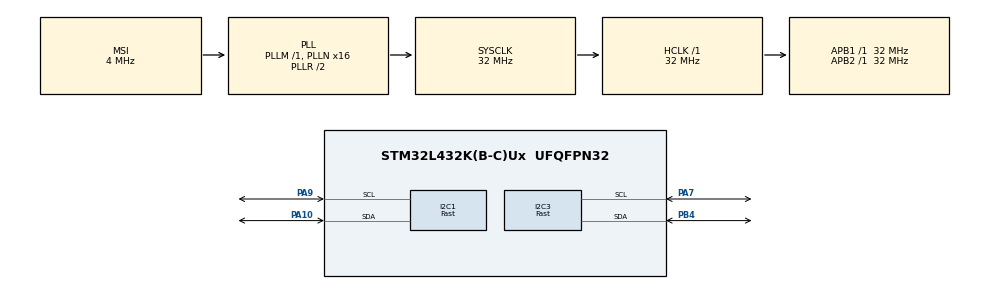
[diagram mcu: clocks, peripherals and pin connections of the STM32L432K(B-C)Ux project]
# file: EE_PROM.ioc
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I2C1.I2C_Speed_Mode=I2C_Fast
I2C1.Timing=0x00300F38
I2C3.I2C_Speed_Mode=I2C_Fast
I2C3.Timing=0x00300F38
Mcu.Family=STM32L4
Mcu.Name=STM32L432K(B-C)Ux
Mcu.Package=UFQFPN32
NVIC.PriorityGroup=NVIC_PRIORITYGROUP_4
PA10.Mode=I2C
PA10.Signal=I2C1_SDA
PA13\ (JTMS-SWDIO).Mode=Serial_Wire
PA13\ (JTMS-SWDIO).Signal=SYS_JTMS-SWDIO
PA14\ (JTCK-SWCLK).Mode=Serial_Wire
PA14\ (JTCK-SWCLK).Signal=SYS_JTCK-SWCLK
PA7.Mode=I2C
PA7.Signal=I2C3_SCL
PA9.Mode=I2C
PA9.Signal=I2C1_SCL
PB4\ (NJTRST).Mode=I2C
PB4\ (NJTRST).Signal=I2C3_SDA
PC14-OSC32_IN\ (PC14).Mode=LSE-External-Oscillator
PC14-OSC32_IN\ (PC14).Signal=RCC_OSC32_IN
PC15-OSC32_OUT\ (PC15).Mode=LSE-External-Oscillator
PC15-OSC32_OUT\ (PC15).Signal=RCC_OSC32_OUT
ProjectManager.HeapSize=0x200
ProjectManager.StackSize=0x400
ProjectManager.TargetToolchain=STM32CubeIDE
RCC.AHBFreq_Value=32000000
RCC.APB1Freq_Value=32000000
RCC.APB1TimFreq_Value=32000000
RCC.APB2Freq_Value=32000000
RCC.APB2TimFreq_Value=32000000
RCC.CortexFreq_Value=32000000
RCC.HCLKFreq_Value=32000000
RCC.HSE_VALUE=8000000
RCC.HSI16_VALUE=16000000
RCC.HSI48_VALUE=48000000
RCC.HSI_VALUE=16000000
RCC.MSI_VALUE=4000000
RCC.PLLMUL=RCC_PLLMUL_4
RCC.PLLN=16
RCC.SYSCLKFreq_VALUE=32000000
RCC.SYSCLKSource=RCC_SYSCLKSOURCE_PLLCLK
RCC.VCOOutputFreq_Value=64000000
board=NUCLEO-L432KC

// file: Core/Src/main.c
/* USER CODE BEGIN Header */
/**
  ******************************************************************************
  * @file           : main.c
  * @brief          : Main program body
  ******************************************************************************
  * @attention
  *
  * Copyright (c) 2024 STMicroelectronics.
  * All rights reserved.
  *
  * This software is licensed under terms that can be found in the LICENSE file
  * in the root directory of this software component.
  * If no LICENSE file comes with this software, it is provided AS-IS.
  *
  ******************************************************************************
  */
/* USER CODE END Header */
#include "main.h"

/* USER CODE BEGIN Includes */
#include "app_EEPROM.h"
#include "comm_EEPROM.h"
/* USER CODE END Includes */

I2C_HandleTypeDef hi2c1;
I2C_HandleTypeDef hi2c3;

void SystemClock_Config(void);
static void MX_GPIO_Init(void);
static void MX_I2C1_Init(void);
static void MX_I2C3_Init(void);

int main(void)
{

  /* MCU Configuration--------------------------------------------------------*/

  /* Reset of all peripherals, Initializes the Flash interface and the Systick. */
  HAL_Init();

  /* Configure the system clock */
  SystemClock_Config();

  /* Initialize all configured peripherals */
  MX_GPIO_Init();
  MX_I2C1_Init();
  MX_I2C3_Init();

  /* Infinite loop */
  while (1)
  {

    /* USER CODE BEGIN 3 */

	Application();
  }
  /* USER CODE END 3 */
}

void SystemClock_Config(void)
{
  RCC_OscInitTypeDef RCC_OscInitStruct = {0};
  RCC_ClkInitTypeDef RCC_ClkInitStruct = {0};

  /** Configure the main internal regulator output voltage
  */
  if (HAL_PWREx_ControlVoltageScaling(PWR_REGULATOR_VOLTAGE_SCALE1) != HAL_OK)
  {
    Error_Handler();
  }

  /** Configure LSE Drive Capability
  */
  HAL_PWR_EnableBkUpAccess();
  __HAL_RCC_LSEDRIVE_CONFIG(RCC_LSEDRIVE_LOW);

  /** Initializes the RCC Oscillators according to the specified parameters
  * in the RCC_OscInitTypeDef structure.
  */
  RCC_OscInitStruct.OscillatorType = RCC_OSCILLATORTYPE_LSE|RCC_OSCILLATORTYPE_MSI;
  RCC_OscInitStruct.LSEState = RCC_LSE_ON;
  RCC_OscInitStruct.MSIState = RCC_MSI_ON;
  RCC_OscInitStruct.MSICalibrationValue = 0;
  RCC_OscInitStruct.MSIClockRange = RCC_MSIRANGE_6;
  RCC_OscInitStruct.PLL.PLLState = RCC_PLL_ON;
  RCC_OscInitStruct.PLL.PLLSource = RCC_PLLSOURCE_MSI;
  RCC_OscInitStruct.PLL.PLLM = 1;
  RCC_OscInitStruct.PLL.PLLN = 16;
  RCC_OscInitStruct.PLL.PLLP = RCC_PLLP_DIV7;
  RCC_OscInitStruct.PLL.PLLQ = RCC_PLLQ_DIV2;
  RCC_OscInitStruct.PLL.PLLR = RCC_PLLR_DIV2;
  if (HAL_RCC_OscConfig(&RCC_OscInitStruct) != HAL_OK)
  {
    Error_Handler();
  }

  /** Initializes the CPU, AHB and APB buses clocks
  */
  RCC_ClkInitStruct.ClockType = RCC_CLOCKTYPE_HCLK|RCC_CLOCKTYPE_SYSCLK
                              |RCC_CLOCKTYPE_PCLK1|RCC_CLOCKTYPE_PCLK2;
  RCC_ClkInitStruct.SYSCLKSource = RCC_SYSCLKSOURCE_PLLCLK;
  RCC_ClkInitStruct.AHBCLKDivider = RCC_SYSCLK_DIV1;
  RCC_ClkInitStruct.APB1CLKDivider = RCC_HCLK_DIV1;
  RCC_ClkInitStruct.APB2CLKDivider = RCC_HCLK_DIV1;

  if (HAL_RCC_ClockConfig(&RCC_ClkInitStruct, FLASH_LATENCY_1) != HAL_OK)
  {
    Error_Handler();
  }

  /** Enable MSI Auto calibration
  */
  HAL_RCCEx_EnableMSIPLLMode();
}

static void MX_I2C1_Init(void)
{

  /* USER CODE BEGIN I2C1_Init 0 */
//
  /* USER CODE END I2C1_Init 0 */

  /* USER CODE BEGIN I2C1_Init 1 */
//
  /* USER CODE END I2C1_Init 1 */
  hi2c1.Instance = I2C1;
  hi2c1.Init.Timing = 0x00300F38;
  hi2c1.Init.OwnAddress1 = 0;
  hi2c1.Init.AddressingMode = I2C_ADDRESSINGMODE_7BIT;
  hi2c1.Init.DualAddressMode = I2C_DUALADDRESS_DISABLE;
  hi2c1.Init.OwnAddress2 = 0;
  hi2c1.Init.OwnAddress2Masks = I2C_OA2_NOMASK;
  hi2c1.Init.GeneralCallMode = I2C_GENERALCALL_DISABLE;
  hi2c1.Init.NoStretchMode = I2C_NOSTRETCH_DISABLE;
  if (HAL_I2C_Init(&hi2c1) != HAL_OK)
  {
    Error_Handler();
  }

  /** Configure Analogue filter
  */
  if (HAL_I2CEx_ConfigAnalogFilter(&hi2c1, I2C_ANALOGFILTER_ENABLE) != HAL_OK)
  {
    Error_Handler();
  }

  /** Configure Digital filter
  */
  if (HAL_I2CEx_ConfigDigitalFilter(&hi2c1, 0) != HAL_OK)
  {
    Error_Handler();
  }
  /* USER CODE BEGIN I2C1_Init 2 */
//
  /* USER CODE END I2C1_Init 2 */

}

static void MX_I2C3_Init(void)
{

  hi2c3.Instance = I2C3;
  hi2c3.Init.Timing = 0x00300F38;
  hi2c3.Init.OwnAddress1 = 0;
  hi2c3.Init.AddressingMode = I2C_ADDRESSINGMODE_7BIT;
  hi2c3.Init.DualAddressMode = I2C_DUALADDRESS_DISABLE;
  hi2c3.Init.OwnAddress2 = 0;
  hi2c3.Init.OwnAddress2Masks = I2C_OA2_NOMASK;
  hi2c3.Init.GeneralCallMode = I2C_GENERALCALL_DISABLE;
  hi2c3.Init.NoStretchMode = I2C_NOSTRETCH_DISABLE;
  if (HAL_I2C_Init(&hi2c3) != HAL_OK)
  {
    Error_Handler();
  }

  /** Configure Analogue filter
  */
  if (HAL_I2CEx_ConfigAnalogFilter(&hi2c3, I2C_ANALOGFILTER_ENABLE) != HAL_OK)
  {
    Error_Handler();
  }

  /** Configure Digital filter
  */
  if (HAL_I2CEx_ConfigDigitalFilter(&hi2c3, 0) != HAL_OK)
  {
    Error_Handler();
  }

}

static void MX_GPIO_Init(void)
{

  /* GPIO Ports Clock Enable */
  __HAL_RCC_GPIOC_CLK_ENABLE();
  __HAL_RCC_GPIOA_CLK_ENABLE();
  __HAL_RCC_GPIOB_CLK_ENABLE();

}

/* USER CODE BEGIN 4 */
//
/* USER CODE END 4 */

void Error_Handler(void)
{
  __disable_irq();
  while (1)
  {
  }
}
